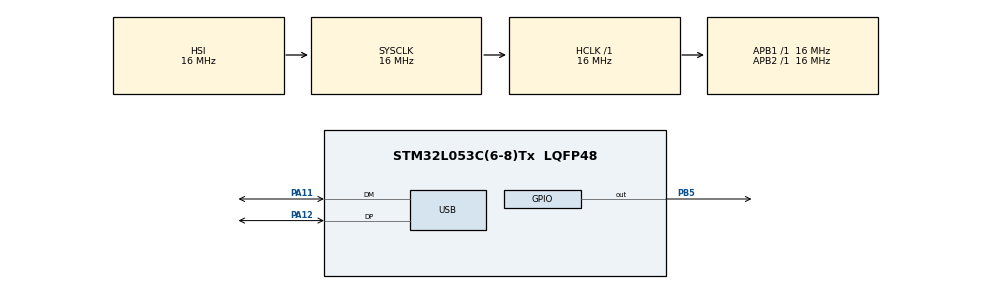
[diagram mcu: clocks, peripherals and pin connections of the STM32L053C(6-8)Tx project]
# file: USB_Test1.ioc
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Mcu.Family=STM32L0
Mcu.Name=STM32L053C(6-8)Tx
Mcu.Package=LQFP48
NVIC.USB_IRQn=true\:0\:0\:false\:false\:true\:true
PA11.Mode=Device
PA11.Signal=USB_DM
PA12.Mode=Device
PA12.Signal=USB_DP
PA13.Mode=Serial_Wire
PA13.Signal=SYS_SWDIO
PA14.Mode=Serial_Wire
PA14.Signal=SYS_SWCLK
PB5.Signal=GPIO_Output
ProjectManager.HeapSize=0x200
ProjectManager.StackSize=0x400
ProjectManager.TargetToolchain=TrueSTUDIO
RCC.AHBFreq_Value=16000000
RCC.APB1Freq_Value=16000000
RCC.APB1TimFreq_Value=16000000
RCC.APB2Freq_Value=16000000
RCC.APB2TimFreq_Value=16000000
RCC.HCLKFreq_Value=16000000
RCC.HSE_VALUE=8000000
RCC.HSI16_VALUE=16000000
RCC.HSI48MClockSelection=RCC_USBCLKSOURCE_HSI48
RCC.HSI48_VALUE=48000000
RCC.HSI_VALUE=16000000
RCC.LSE_VALUE=32768
RCC.MSI_VALUE=2097000
RCC.PLLMUL=RCC_PLLMUL_6
RCC.SYSCLKFreq_VALUE=16000000
RCC.SYSCLKSource=RCC_SYSCLKSOURCE_HSI
RCC.VCOOutputFreq_Value=96000000
USB_DEVICE.CLASS_NAME_FS=CDC
USB_DEVICE.VirtualMode=Cdc
USB_DEVICE.VirtualModeFS=Cdc_FS
VP_USB_DEVICE_VS_USB_DEVICE_CDC_FS.Mode=CDC_FS
board=custom

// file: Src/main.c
/* USER CODE BEGIN Header */
/**
  ******************************************************************************
  * @file           : main.c
  * @brief          : Main program body
  ******************************************************************************
  * This notice applies to any and all portions of this file
  * that are not between comment pairs USER CODE BEGIN and
  * USER CODE END. Other portions of this file, whether
  * inserted by the user or by software development tools
  * are owned by their respective copyright owners.
  *
  * Copyright (c) 2020 STMicroelectronics International N.V.
  * All rights reserved.
  *
  * Redistribution and use in source and binary forms, with or without
  * modification, are permitted, provided that the following conditions are met:
  *
  * 1. Redistribution of source code must retain the above copyright notice,
  *    this list of conditions and the following disclaimer.
  * 2. Redistributions in binary form must reproduce the above copyright notice,
  *    this list of conditions and the following disclaimer in the documentation
  *    and/or other materials provided with the distribution.
  * 3. Neither the name of STMicroelectronics nor the names of other
  *    contributors to this software may be used to endorse or promote products
  *    derived from this software without specific written permission.
  * 4. This software, including modifications and/or derivative works of this
  *    software, must execute solely and exclusively on microcontroller or
  *    microprocessor devices manufactured by or for STMicroelectronics.
  * 5. Redistribution and use of this software other than as permitted under
  *    this license is void and will automatically terminate your rights under
  *    this license.
  *
  * THIS SOFTWARE IS PROVIDED BY STMICROELECTRONICS AND CONTRIBUTORS "AS IS"
  * AND ANY EXPRESS, IMPLIED OR STATUTORY WARRANTIES, INCLUDING, BUT NOT
  * LIMITED TO, THE IMPLIED WARRANTIES OF MERCHANTABILITY, FITNESS FOR A
  * PARTICULAR PURPOSE AND NON-INFRINGEMENT OF THIRD PARTY INTELLECTUAL PROPERTY
  * RIGHTS ARE DISCLAIMED TO THE FULLEST EXTENT PERMITTED BY LAW. IN NO EVENT
  * SHALL STMICROELECTRONICS OR CONTRIBUTORS BE LIABLE FOR ANY DIRECT, INDIRECT,
  * INCIDENTAL, SPECIAL, EXEMPLARY, OR CONSEQUENTIAL DAMAGES (INCLUDING, BUT NOT
  * LIMITED TO, PROCUREMENT OF SUBSTITUTE GOODS OR SERVICES; LOSS OF USE, DATA,
  * OR PROFITS; OR BUSINESS INTERRUPTION) HOWEVER CAUSED AND ON ANY THEORY OF
  * LIABILITY, WHETHER IN CONTRACT, STRICT LIABILITY, OR TORT (INCLUDING
  * NEGLIGENCE OR OTHERWISE) ARISING IN ANY WAY OUT OF THE USE OF THIS SOFTWARE,
  * EVEN IF ADVISED OF THE POSSIBILITY OF SUCH DAMAGE.
  *
  ******************************************************************************
  */
/* USER CODE END Header */

#include "main.h"
#include "usb_device.h"

void SystemClock_Config(void);
static void MX_GPIO_Init(void);
/* USER CODE BEGIN PFP */
	extern uint8_t CDC_Transmit_FS(uint8_t* Buf, uint16_t Len);
/* USER CODE END PFP */

int main(void)
{
  /* USER CODE BEGIN 1 */
	//pb5
	uint8_t buffer1[] = "\r\nExample Packet Structure:\r\nName,Latitude,Longitude,Heart-rate,SPIO2\r\nLucas,40.257475,-86.547768,110,97%\r\n\r\n";
	uint8_t buffer2[] = "Name,Latitude,Longitude,Heart-rate,SPIO2\r\n";
	uint8_t buffer3[] = "Lucas,40.257475,-86.547768,110,97%\r\n\r\n";
  /* USER CODE END 1 */

  /* MCU Configuration--------------------------------------------------------*/

  /* Reset of all peripherals, Initializes the Flash interface and the Systick. */
  HAL_Init();

  /* Configure the system clock */
  SystemClock_Config();

  /* Initialize all configured peripherals */
  MX_GPIO_Init();
  MX_USB_DEVICE_Init();

  /* Infinite loop */
  while (1)
  {

  }
}

void SystemClock_Config(void)
{
  RCC_OscInitTypeDef RCC_OscInitStruct = {0};
  RCC_ClkInitTypeDef RCC_ClkInitStruct = {0};
  RCC_PeriphCLKInitTypeDef PeriphClkInit = {0};

  /**Configure the main internal regulator output voltage
  */
  __HAL_PWR_VOLTAGESCALING_CONFIG(PWR_REGULATOR_VOLTAGE_SCALE1);
  /**Initializes the CPU, AHB and APB busses clocks
  */
  RCC_OscInitStruct.OscillatorType = RCC_OSCILLATORTYPE_HSI|RCC_OSCILLATORTYPE_HSI48;
  RCC_OscInitStruct.HSIState = RCC_HSI_ON;
  RCC_OscInitStruct.HSICalibrationValue = RCC_HSICALIBRATION_DEFAULT;
  RCC_OscInitStruct.HSI48State = RCC_HSI48_ON;
  RCC_OscInitStruct.PLL.PLLState = RCC_PLL_NONE;
  if (HAL_RCC_OscConfig(&RCC_OscInitStruct) != HAL_OK)
  {
    Error_Handler();
  }
  /**Initializes the CPU, AHB and APB busses clocks
  */
  RCC_ClkInitStruct.ClockType = RCC_CLOCKTYPE_HCLK|RCC_CLOCKTYPE_SYSCLK
                              |RCC_CLOCKTYPE_PCLK1|RCC_CLOCKTYPE_PCLK2;
  RCC_ClkInitStruct.SYSCLKSource = RCC_SYSCLKSOURCE_HSI;
  RCC_ClkInitStruct.AHBCLKDivider = RCC_SYSCLK_DIV1;
  RCC_ClkInitStruct.APB1CLKDivider = RCC_HCLK_DIV1;
  RCC_ClkInitStruct.APB2CLKDivider = RCC_HCLK_DIV1;

  if (HAL_RCC_ClockConfig(&RCC_ClkInitStruct, FLASH_LATENCY_0) != HAL_OK)
  {
    Error_Handler();
  }
  PeriphClkInit.PeriphClockSelection = RCC_PERIPHCLK_USB;
  PeriphClkInit.UsbClockSelection = RCC_USBCLKSOURCE_HSI48;
  if (HAL_RCCEx_PeriphCLKConfig(&PeriphClkInit) != HAL_OK)
  {
    Error_Handler();
  }
}

static void MX_GPIO_Init(void)
{
  GPIO_InitTypeDef GPIO_InitStruct = {0};

  /* GPIO Ports Clock Enable */
  __HAL_RCC_GPIOA_CLK_ENABLE();
  __HAL_RCC_GPIOB_CLK_ENABLE();

  /*Configure GPIO pin Output Level */
  HAL_GPIO_WritePin(GPIOB, GPIO_PIN_5, GPIO_PIN_RESET);

  /*Configure GPIO pin : PB5 */
  GPIO_InitStruct.Pin = GPIO_PIN_5;
  GPIO_InitStruct.Mode = GPIO_MODE_OUTPUT_PP;
  GPIO_InitStruct.Pull = GPIO_NOPULL;
  GPIO_InitStruct.Speed = GPIO_SPEED_FREQ_LOW;
  HAL_GPIO_Init(GPIOB, &GPIO_InitStruct);

}

void Error_Handler(void)
{
}

/************************ (C) COPYRIGHT STMicroelectronics *****END OF FILE****/
